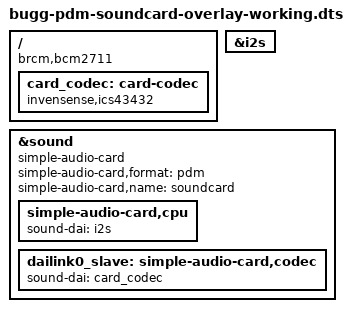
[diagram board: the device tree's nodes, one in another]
/dts-v1/;
/plugin/;

/ {
    compatible = "brcm,bcm2711";

    fragment@0 {
        target = <&i2s>;
        __overlay__ {
            status = "okay";
        };
    };

    fragment@1 {
        target-path = "/";
        __overlay__ {
            card_codec: card-codec {
                #sound-dai-cells = <0>;
                compatible = "invensense,ics43432";
                status = "okay";
            };
        };
    };

// Enable this fragment if your CODEC is the clock master by replacing __dormant__ with __overlay__ and vice versa in fragment 3.
    fragment@2 {
        target = <&sound>;
        master_overlay: __dormant__ {
            compatible = "simple-audio-card";
            simple-audio-card,format = "i2s";
            simple-audio-card,name = "soundcard";
            simple-audio-card,bitclock-master = <&dailink0_master>;
            simple-audio-card,frame-master = <&dailink0_master>;
            status = "okay";
            simple-audio-card,cpu {
                sound-dai = <&i2s>;
            };
            dailink0_master: simple-audio-card,codec {
                sound-dai = <&card_codec>;
            };
        };
    };

    fragment@3 {
        target = <&sound>;
        slave_overlay: __overlay__ {
                compatible = "simple-audio-card";
                simple-audio-card,format = "pdm";
                simple-audio-card,name = "soundcard";
                status = "okay";
                simple-audio-card,cpu {
                    sound-dai = <&i2s>;
                };
                dailink0_slave: simple-audio-card,codec {
                    sound-dai = <&card_codec>;
                };
        };
    };

    __overrides__ {
        alsaname = <&master_overlay>,"simple-audio-card,name",
                    <&slave_overlay>,"simple-audio-card,name";
        compatible = <&card_codec>,"compatible";
        master = <0>,"=2!3";
    };
};

